# STM32WB55x register map
File version: 1.0
CPU: CM4 r0p1, little endian, 4 interrupt priority bits
Registers are 32-bit, read-write, reset 0x0 unless marked. A register's access mark holds for its fields unless they carry their own. Offsets are from the block's base; lines under a group give offsets from that group; [hi:lo] are bit positions; {n}, {i} and the like mark numbered series; 'fields as' and 'values as' point back to an identical list; <NAME> marks a mode.

## Memory map
0x40000000 TIM2 size 0x400
0x40002400 LCD size 0x400
0x40002800 RTC size 0x400
0x40002C00 WWDG size 0x400
0x40003000 IWDG size 0x400
0x40003800 SPI2 size 0x400
0x40005400 I2C1 size 0x400
0x40005C00 I2C3 size 0x400
0x40006000 CRS size 0x400
0x40006800 USB_FS size 0x400
0x40007C00 LPTIM1 size 0x400
0x40008000 LPTIM2 size 0x400
0x40010000 SYSCFG size 0x30
0x40010000 SYSCFG2 size 0x200
0x40010030 VREFBUF size 0xD0
0x40010200 COMP size 0x200
0x40012C00 TIM1 size 0x400
0x40013000 SPI1 size 0x400
0x40013800 USART1 size 0x400
0x40014400 TIM16 size 0x400
0x40014800 TIM17 size 0x400
0x40015400 SAI size 0x400
0x40020000 DMA1 size 0x400
0x40020400 DMA2 size 0x400
0x40020800 DMAMUX size 0x400
0x40023000 CRC size 0x400
0x40024000 TSC size 0x400
0x48000000 GPIOA size 0x400
0x48000400 GPIOB size 0x400
0x48000800 GPIOC size 0x400
0x48000C00 GPIOD size 0x400
0x48001000 GPIOE size 0x400
0x48001C00 GPIOH size 0x400
0x50040000 ADC size 0x400
0x50050400 AES1 size 0x400
0x58000000 RCC size 0x400
0x58000400 PWR size 0x400
0x58000800 EXTI size 0x400
0x58000C00 IPCC size 0x400
0x58001000 RNG size 0x400
0x58001400 HSEM size 0x400
0x58001800 AES2 size 0x400
0x58002000 PKA size 0x400
0x58004000 FLASH size 0x400
0xA0001000 QUADSPI size 0x400
0xE000E000 NVIC size 0x1001 — Nested Vectored Interrupt Controller
0xE000E010 STK size 0x11 — SysTick timer
0xE000ED00 SCB size 0x41 — System control block
0xE000ED90 MPU size 0x15 — Memory protection unit
0xE000EF34 FPU size 0xD — Floting point unit
0xE0042000 DBGMCU size 0x15 — MCU debug component

## Interrupts
0 WWDG
1 PVD (EXTI)
2 TAMP (RTC)
3 RTC_WKUP (RTC)
4 FLASH
5 RCC
6 EXTI0 (EXTI)
7 EXTI1 (EXTI)
8 EXTI2 (EXTI)
9 EXTI3 (EXTI)
10 EXTI4 (EXTI)
11 DMA1_CH1 (DMA1)
12 DMA1_CH2 (DMA1)
13 DMA1_CH3 (DMA1)
14 DMA1_CH4 (DMA1)
15 DMA1_CH5 (DMA1)
16 DMA1_CH6 (DMA1)
17 DMA1_CH7 (DMA1)
18 ADC
19 USB_HP (USB_FS)
20 USB_LP (USB_FS)
21 C2SEV_PWR_C2H (PWR)
22 COMP
23 EXTI9_5 (EXTI)
24 TIM1_BRK (TIM1)
25 TIM1_UP_TIM16 (TIM16)
26 TIM1_TRG_COM_TIM17 (TIM17)
27 TIM1_CC (TIM1)
28 TIM2
30 I2C1_EV (I2C1)
31 I2C1_ER (I2C1)
32 I2C3_EV (I2C3)
33 I2C3_ER (I2C3)
34 SPI1
35 SPI2
36 USART1
38 SAI
39 TSC
40 EXTI15_10 (EXTI)
41 RTC_ALARM (RTC)
42 CRS
43 PWR_SOTF_BLEACT_802ACT_RFPHASE (PWR)
44 IPCC_C1_RX (IPCC)
45 IPCC_C1_TX (IPCC)
46 HSEM
47 LPTIM1
48 LPTIM2
49 LCD
50 QUADSPI
51 AES1
52 AES2
53 RNG
54 FPU — Floating point unit interrupt
55 DMA2_CH1 (DMA2)
56 DMA2_CH2 (DMA2)
57 DMA2_CH3 (DMA2)
58 DMA2_CH4 (DMA2)
59 DMA2_CH5 (DMA2)
60 DMA2_CH6 (DMA2)
61 DMA2_CH7 (DMA2)
62 DMAMUX_OVR (DMAMUX)

## ADC
Base 0x50040000
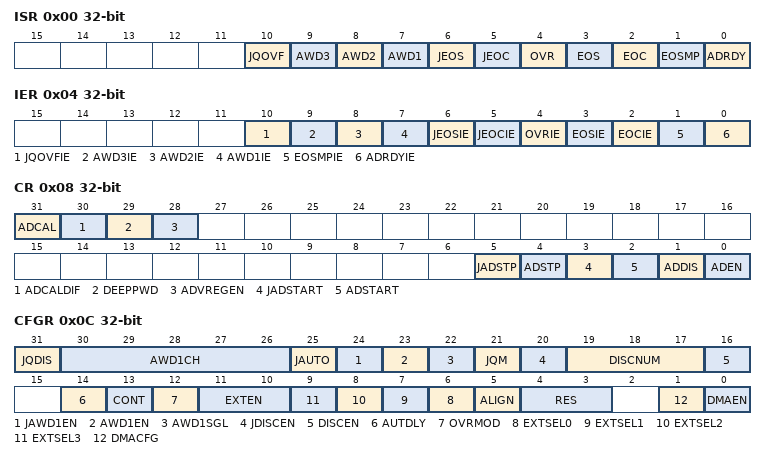
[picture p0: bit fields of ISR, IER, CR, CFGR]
0x00 ISR
  [10] JQOVF, [9] AWD3, [8] AWD2, [7] AWD1, [6] JEOS, [5] JEOC, [4] OVR, [3] EOS, [2] EOC, [1] EOSMP, [0] ADRDY
0x04 IER
  [10] JQOVFIE, [9] AWD3IE, [8] AWD2IE, [7] AWD1IE, [6] JEOSIE, [5] JEOCIE, [4] OVRIE, [3] EOSIE, [2] EOCIE, [1] EOSMPIE, [0] ADRDYIE
0x08 CR
  [31] ADCAL, [30] ADCALDIF, [29] DEEPPWD, [28] ADVREGEN, [5] JADSTP, [4] ADSTP, [3] JADSTART, [2] ADSTART, [1] ADDIS, [0] ADEN
0x0C CFGR
  [31] JQDIS, [30:26] AWD1CH, [25] JAUTO, [24] JAWD1EN, [23] AWD1EN, [22] AWD1SGL, [21] JQM, [20] JDISCEN, [19:17] DISCNUM, [16] DISCEN, [14] AUTDLY, [13] CONT, [12] OVRMOD, [11:10] EXTEN, [n+6] EXTSEL{n} (n=0..3), [5] ALIGN, [4:3] RES, [1] DMACFG, [0] DMAEN
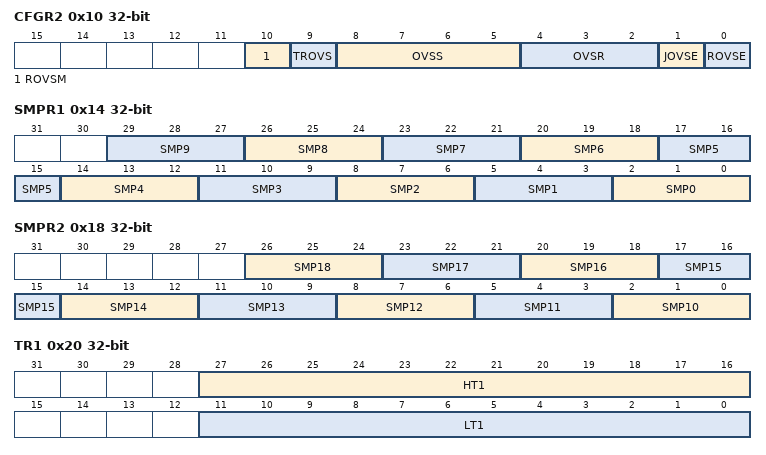
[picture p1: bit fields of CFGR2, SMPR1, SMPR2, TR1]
0x10 CFGR2
  [10] ROVSM, [9] TROVS, [8:5] OVSS, [4:2] OVSR, [1] JOVSE, [0] ROVSE
0x14 SMPR1
  [3n+2:3n] SMP{n} (n=0..9)
0x18 SMPR2
  [3n-28:3n-30] SMP{n} (n=10..18)
0x20 TR1
  [27:16] HT1, [11:0] LT1
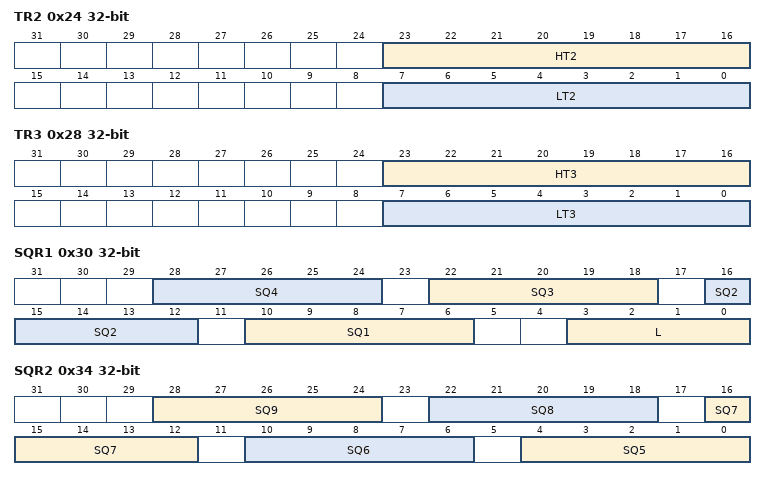
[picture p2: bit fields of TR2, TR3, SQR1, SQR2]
0x24 TR2
  [23:16] HT2, [7:0] LT2
0x28 TR3
  [23:16] HT3, [7:0] LT3
0x30 SQR1
  [6n+4:6n] SQ{n} (n=1..4), [3:0] L
0x34 SQR2
  [6n-26:6n-30] SQ{n} (n=5..9)
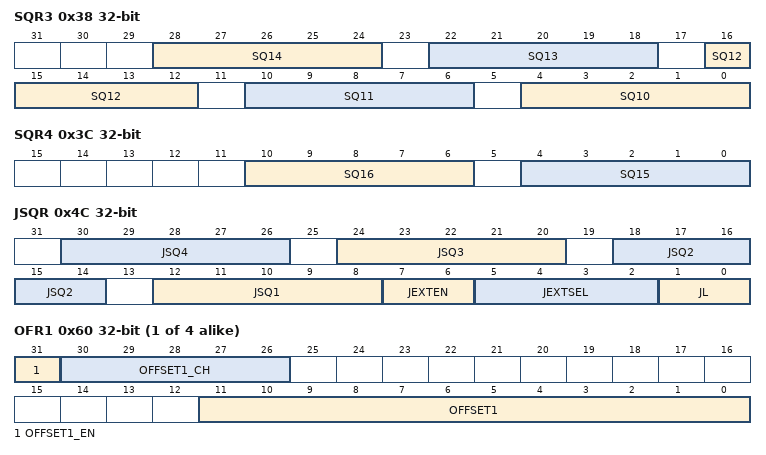
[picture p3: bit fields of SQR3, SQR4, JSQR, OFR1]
0x38 SQR3
  [6n-56:6n-60] SQ{n} (n=10..14)
0x3C SQR4
  [10:6] SQ16, [4:0] SQ15
0x40 DR
  [15:0] RDATA
0x4C JSQR
  [6n+6:6n+2] JSQ{n} (n=1..4), [7:6] JEXTEN, [5:2] JEXTSEL, [1:0] JL
{0x5C+4i} OFR{i} (i=1..4)
  [31] OFFSET{i}_EN, [30:26] OFFSET{i}_CH, [11:0] OFFSET{i}
{0x7C+4i} JDR{i} (i=1..4)
  [15:0] JDATA{i}
0xA0 AWD2CR
  [18:0] AWD2CH
0xA4 AWD3CR
  [18:0] AWD3CH
0xB0 DIFSEL
  [18:0] DIFSEL
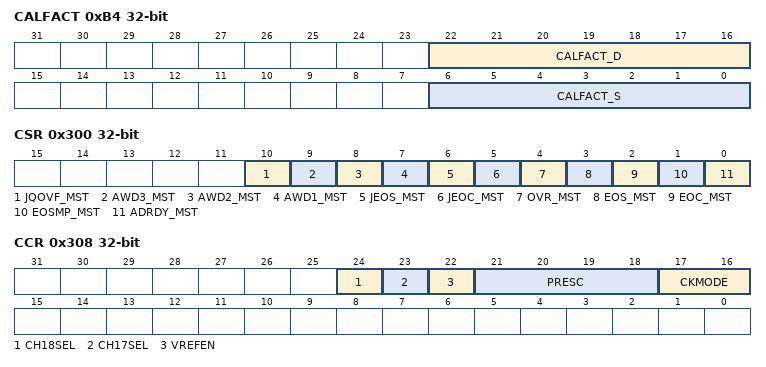
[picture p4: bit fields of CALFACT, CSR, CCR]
0xB4 CALFACT
  [22:16] CALFACT_D, [6:0] CALFACT_S
0x300 CSR
  [10] JQOVF_MST, [9] AWD3_MST, [8] AWD2_MST, [7] AWD1_MST, [6] JEOS_MST, [5] JEOC_MST, [4] OVR_MST, [3] EOS_MST, [2] EOC_MST, [1] EOSMP_MST, [0] ADRDY_MST
0x308 CCR
  [24] CH18SEL, [23] CH17SEL, [22] VREFEN, [21:18] PRESC, [17:16] CKMODE
